AUTOSAR XML (schema 00046)
package /ComponentTypes
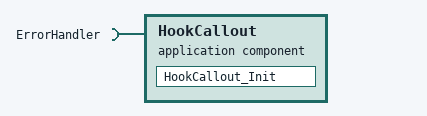
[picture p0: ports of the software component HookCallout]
  application sw component type HookCallout
    require port ErrorHandler: client-com-spec=ReportError, required-interface=ErrorHandler
    behavior HookCallout_InternalBehavior
      init event HookCallout_InitEvent: start-on-event=HookCallout_Init
      runnable HookCallout_Init
        sync call SC_ErrorHandler_ReportError: operation=ErrorHandler.ReportError
  swc implementation HookCallout_Implementation: behavior=HookCallout_InternalBehavior
    code-descriptors:
      code Default: artifact-descriptors=autosar-engineering-object=category=SWSRC
